# STM32L073VZT7 register map
File version: 1.0
STM32L073CBT6,STM32L073CBU6,STM32L073CZT3,STM32L073CZT6,STM32L073CZT7,STM32L073CZU3,STM32L073CZU6,STM32L073CZU7,STM32L073CZY3,STM32L073CZY6,STM32L073CZY7,STM32L073RBH6,STM32L073RBT6,STM32L073RZH3,STM32L073RZH6,STM32L073RZH7,STM32L073RZI3,STM32L073RZI6,STM32L073RZI7,STM32L073RZT3,STM32L073RZT6,STM32L073RZT7,STM32L073V8I6,STM32L073V8T6,STM32L073V8T7,STM32L073VBI3,STM32L073VBI6,STM32L073VBI7,STM32L073VBT6,STM32L073VBT7,STM32L073VZI3,STM32L073VZI6,STM32L073VZI7,STM32L073VZT3,STM32L073VZT6,STM32L073VZT7
Registers are 32-bit, access not given, reset 0x0 unless marked. A register's access mark holds for its fields unless they carry their own. Offsets are from the block's base; lines under a group give offsets from that group; [hi:lo] are bit positions; {n}, {i} and the like mark numbered series; 'fields as' and 'values as' point back to an identical list; <NAME> marks a mode.

## Memory map
0x1FF80000 OB
0x40000000 TIM2
0x40000400 TIM3
0x40001000 TIM6
0x40001400 TIM7
0x40002400 LCD
0x40002800 RTC
0x40002C00 WWDG
0x40003000 IWDG
0x40003800 SPI2
0x40004400 USART2
0x40004800 LPUART1
0x40004C00 USART4
0x40005000 USART5
0x40005400 I2C1
0x40005800 I2C2
0x40005C00 USB
0x40006C00 CRS
0x40007000 PWR
0x40007400 DAC
0x40007400 DAC1
0x40007800 I2C3
0x40007C00 LPTIM1
0x40010000 SYSCFG
0x40010018 COMP12_COMMON
0x40010018 COMP1
0x4001001C COMP2
0x40010400 EXTI
0x40010800 TIM21
0x40011400 TIM22
0x40011C00 FIREWALL
0x40012400 ADC1
0x40020000 DMA1
0x400200A8 DMA1_CSELR
0x40021000 RCC
0x40022000 FLASH
0x40023000 CRC
0x40024000 TSC
0x40025000 RNG
0x50000000 GPIOA
0x50000400 GPIOB
0x50000800 GPIOC
0x50000C00 GPIOD
0x50001000 GPIOE
0x50001C00 GPIOH

## OB
Base 0x1FF80000
0x00 RDP
0x04 USER
0x08 WRP01
0x0C WRP23
0x10 WRP45

## TIM2
Base 0x40000000
Same registers: TIM3 0x40000400, TIM6 0x40001000, TIM7 0x40001400, TIM21 0x40010800, TIM22 0x40011400
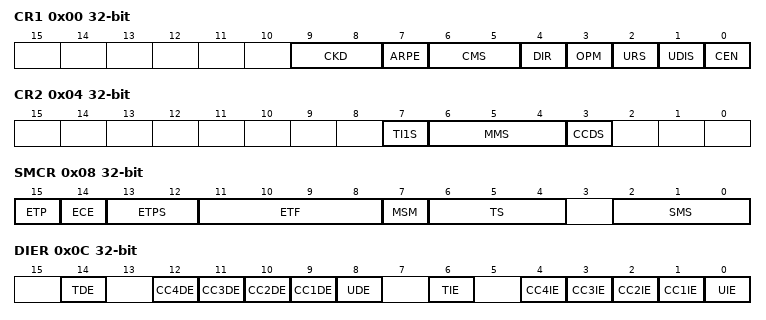
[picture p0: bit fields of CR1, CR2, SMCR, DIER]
0x00 CR1
  [9:8] CKD, [7] ARPE, [6:5] CMS, [4] DIR, [3] OPM, [2] URS, [1] UDIS, [0] CEN
0x04 CR2
  [7] TI1S, [6:4] MMS, [3] CCDS
0x08 SMCR
  [15] ETP, [14] ECE, [13:12] ETPS, [11:8] ETF, [7] MSM, [6:4] TS, [2:0] SMS
0x0C DIER
  [14] TDE, [n+8] CC{n}DE (n=1..4), [8] UDE, [6] TIE, [n] CC{n}IE (n=1..4), [0] UIE
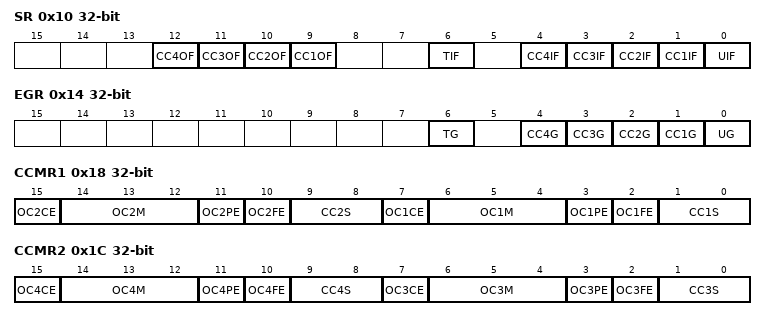
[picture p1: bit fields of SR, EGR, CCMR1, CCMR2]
0x10 SR
  [n+8] CC{n}OF (n=1..4), [6] TIF, [n] CC{n}IF (n=1..4), [0] UIF
0x14 EGR
  [6] TG, [n] CC{n}G (n=1..4), [0] UG
0x18 CCMR1
  [15] OC2CE, [14:12] OC2M, [11] OC2PE, [10] OC2FE, [9:8] CC2S, [7] OC1CE, [6:4] OC1M, [3] OC1PE, [2] OC1FE, [1:0] CC1S
0x1C CCMR2
  [15] OC4CE, [14:12] OC4M, [11] OC4PE, [10] OC4FE, [9:8] CC4S, [7] OC3CE, [6:4] OC3M, [3] OC3PE, [2] OC3FE, [1:0] CC3S
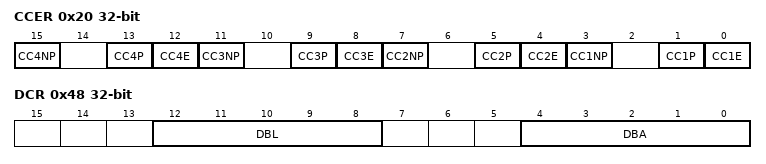
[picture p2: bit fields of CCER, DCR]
0x20 CCER
  [4n-1] CC{n}NP (n=1..4), [4n-3] CC{n}P (n=1..4), [4n-4] CC{n}E (n=1..4)
0x24 CNT
  [15:0] CNT
0x28 PSC
  [15:0] PSC
0x2C ARR
  [15:0] ARR
{0x30+4i} CCR{i} (i=1..4)
  [15:0] CCR{i}
0x48 DCR
  [12:8] DBL, [4:0] DBA
0x4C DMAR
  [15:0] DMAB
0x50 OR

## LCD
Base 0x40002400
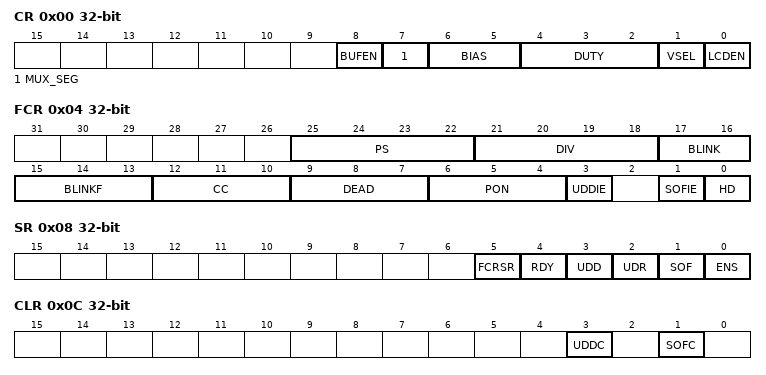
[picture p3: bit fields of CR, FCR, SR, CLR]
0x00 CR
  [8] BUFEN, [7] MUX_SEG, [6:5] BIAS, [4:2] DUTY, [1] VSEL, [0] LCDEN
0x04 FCR
  [25:22] PS, [21:18] DIV, [17:16] BLINK, [15:13] BLINKF, [12:10] CC, [9:7] DEAD, [6:4] PON, [3] UDDIE, [1] SOFIE, [0] HD
0x08 SR
  [5] FCRSR, [4] RDY, [3] UDD, [2] UDR, [1] SOF, [0] ENS
0x0C CLR
  [3] UDDC, [1] SOFC
0x14 RAM.0
  [31:0] SEGMENT_DATA
0x18 RAM.1
  [31:0] SEGMENT_DATA
0x1C RAM.2
  [31:0] SEGMENT_DATA
0x20 RAM.3
  [31:0] SEGMENT_DATA
0x24 RAM.4
  [31:0] SEGMENT_DATA
0x28 RAM.5
  [31:0] SEGMENT_DATA
0x2C RAM.6
  [31:0] SEGMENT_DATA
0x30 RAM.7
  [31:0] SEGMENT_DATA
0x34 RAM.8
  [31:0] SEGMENT_DATA
0x38 RAM.9
  [31:0] SEGMENT_DATA
0x3C RAM.10
  [31:0] SEGMENT_DATA
0x40 RAM.11
  [31:0] SEGMENT_DATA
0x44 RAM.12
  [31:0] SEGMENT_DATA
0x48 RAM.13
  [31:0] SEGMENT_DATA
0x4C RAM.14
  [31:0] SEGMENT_DATA
0x50 RAM.15
  [31:0] SEGMENT_DATA

## RTC
Base 0x40002800
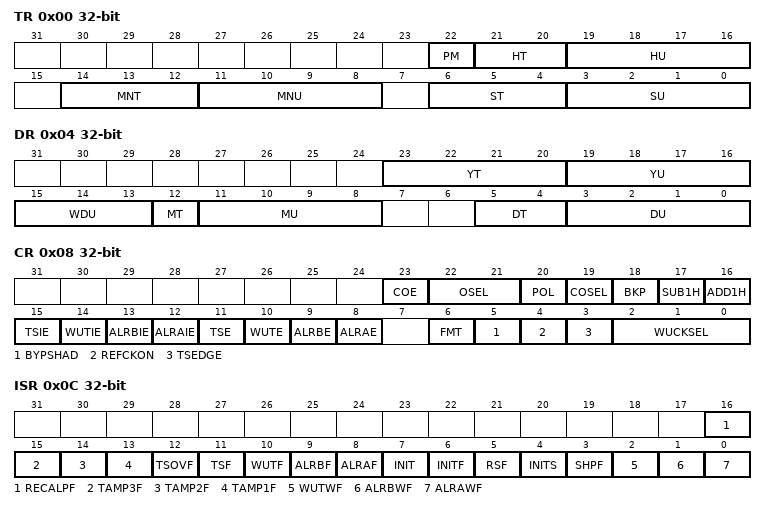
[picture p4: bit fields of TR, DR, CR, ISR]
0x00 TR
  [22] PM, [21:20] HT, [19:16] HU, [14:12] MNT, [11:8] MNU, [6:4] ST, [3:0] SU
0x04 DR
  [23:20] YT, [19:16] YU, [15:13] WDU, [12] MT, [11:8] MU, [5:4] DT, [3:0] DU
0x08 CR
  [23] COE, [22:21] OSEL, [20] POL, [19] COSEL, [18] BKP, [17] SUB1H, [16] ADD1H, [15] TSIE, [14] WUTIE, [13] ALRBIE, [12] ALRAIE, [11] TSE, [10] WUTE, [9] ALRBE, [8] ALRAE, [6] FMT, [5] BYPSHAD, [4] REFCKON, [3] TSEDGE, [2:0] WUCKSEL
0x0C ISR
  [16] RECALPF, [15] TAMP3F, [14] TAMP2F, [13] TAMP1F, [12] TSOVF, [11] TSF, [10] WUTF, [9] ALRBF, [8] ALRAF, [7] INIT, [6] INITF, [5] RSF, [4] INITS, [3] SHPF, [2] WUTWF, [1] ALRBWF, [0] ALRAWF
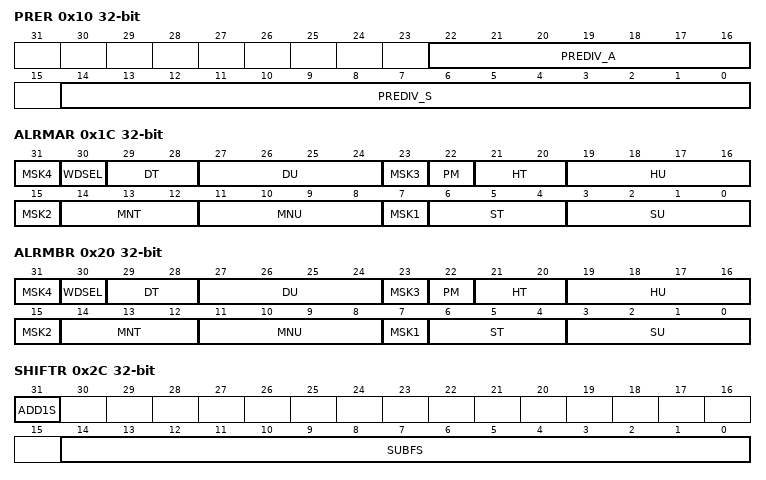
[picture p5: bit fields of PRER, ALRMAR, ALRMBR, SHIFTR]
0x10 PRER
  [22:16] PREDIV_A, [14:0] PREDIV_S
0x14 WUTR
  [15:0] WUT
0x1C ALRMAR
  [8n-1] MSK{n} (n=1..4), [30] WDSEL, [29:28] DT, [27:24] DU, [22] PM, [21:20] HT, [19:16] HU, [14:12] MNT, [11:8] MNU, [6:4] ST, [3:0] SU
0x20 ALRMBR
  fields as ALRMAR
0x24 WPR
  [7:0] KEY
0x28 SSR
  [15:0] SS
0x2C SHIFTR
  [31] ADD1S, [14:0] SUBFS
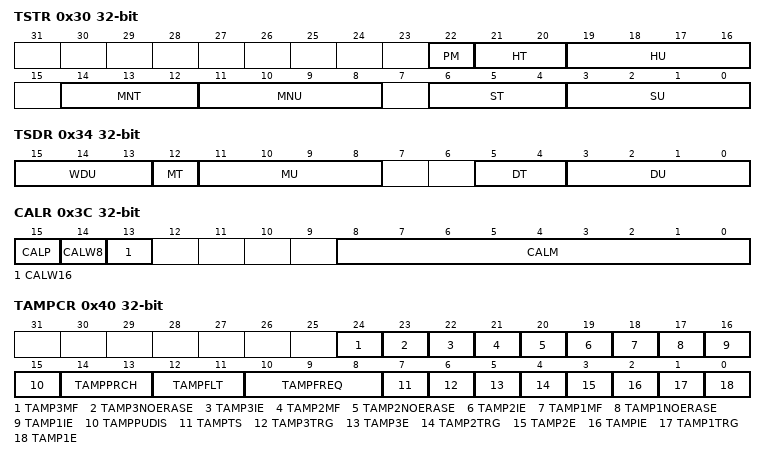
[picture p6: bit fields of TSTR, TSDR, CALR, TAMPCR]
0x30 TSTR
  fields as TR
0x34 TSDR
  [15:13] WDU, [12] MT, [11:8] MU, [5:4] DT, [3:0] DU
0x38 TSSSR
  [15:0] SS
0x3C CALR
  [15] CALP, [14] CALW8, [13] CALW16, [8:0] CALM
0x40 TAMPCR
  [24] TAMP3MF, [23] TAMP3NOERASE, [22] TAMP3IE, [21] TAMP2MF, [20] TAMP2NOERASE, [19] TAMP2IE, [18] TAMP1MF, [17] TAMP1NOERASE, [16] TAMP1IE, [15] TAMPPUDIS, [14:13] TAMPPRCH, [12:11] TAMPFLT, [10:8] TAMPFREQ, [7] TAMPTS, [6] TAMP3TRG, [5] TAMP3E, [4] TAMP2TRG, [3] TAMP2E, [2] TAMPIE, [1] TAMP1TRG, [0] TAMP1E
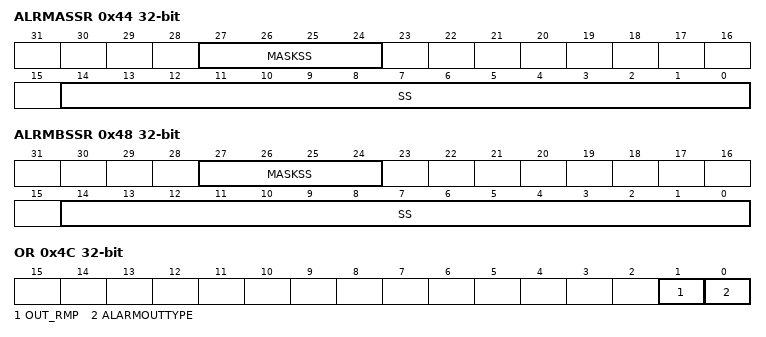
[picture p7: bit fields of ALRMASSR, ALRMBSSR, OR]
0x44 ALRMASSR
  [27:24] MASKSS, [14:0] SS
0x48 ALRMBSSR
  [27:24] MASKSS, [14:0] SS
0x4C OR
  [1] OUT_RMP, [0] ALARMOUTTYPE
{0x50+4i} BKP{i}R (i=0..4)
